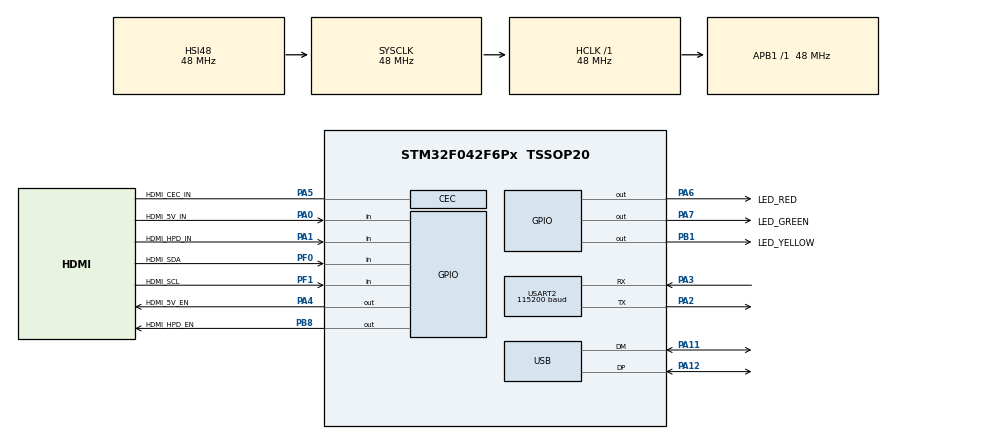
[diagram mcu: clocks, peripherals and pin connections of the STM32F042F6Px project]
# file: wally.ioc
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Mcu.Family=STM32F0
VP_SYS_VS_PINREMAP.Mode=PINREMAP
USB_DEVICE.CLASS_NAME_FS=CDC
NVIC.USB_IRQn=true\:0\:0\:false\:false\:true\:false\:true
USB_DEVICE.VirtualModeFS=Cdc_FS
PA3.GPIO_PuPd=GPIO_PULLUP
PA0.GPIO_Label=HDMI_5V_IN
PA2.GPIO_Speed=GPIO_SPEED_FREQ_LOW
PA11.Mode=Device
PA6.GPIO_Label=LED_RED
PA3.GPIO_Speed=GPIO_SPEED_FREQ_LOW
NVIC.USART2_IRQn=true\:0\:0\:false\:false\:true\:true\:true
USART2.BaudRate=115200
RCC.SYSCLKSource=RCC_SYSCLKSOURCE_HSI48
ProjectManager.StackSize=0x200
PA3.Mode=Asynchronous
PA13.Signal=SYS_SWDIO
PB8.GPIO_Label=HDMI_HPD_EN
PA12.Signal=USB_DP
ProjectManager.TargetToolchain=STM32CubeIDE
PF0-OSC_IN.GPIO_PuPd=GPIO_PULLUP
RCC.HCLKFreq_Value=48000000
VP_USB_DEVICE_VS_USB_DEVICE_CDC_FS.Mode=CDC_FS
PF1-OSC_OUT.GPIO_PuPd=GPIO_PULLUP
PA1.Signal=GPIO_Input
RCC.AHBFreq_Value=48000000
PA5.Signal=CEC
PF0-OSC_IN.GPIO_Label=HDMI_SDA
board=custom
USART2.VirtualMode-Asynchronous=VM_ASYNC
PA14.Mode=Serial_Wire
PB1.GPIO_Label=LED_YELLOW
PF1-OSC_OUT.GPIO_Label=HDMI_SCL
PA1.GPIO_Label=HDMI_HPD_IN
PA13.Mode=Serial_Wire
Mcu.Name=STM32F042F6Px
PA2.Signal=USART2_TX
PA0.Signal=GPIO_Input
PA4.Signal=GPIO_Output
NVIC.CEC_CAN_IRQn=true\:0\:0\:false\:false\:true\:false\:true
RCC.SYSCLKFreq_VALUE=48000000
Mcu.Package=TSSOP20
PA6.Signal=GPIO_Output
PB1.Signal=GPIO_Output
PA7.GPIO_Label=LED_GREEN
PA12.Mode=Device
PA5.GPIO_Label=HDMI_CEC_IN
PA11.Signal=USB_DM
PA14.Signal=SYS_SWCLK
ProjectManager.HeapSize=0x400
RCC.APB1TimFreq_Value=48000000
PB8.Signal=GPIO_Output
PA2.Mode=Asynchronous
PF0-OSC_IN.Signal=GPIO_Input
RCC.APB1Freq_Value=48000000
USB_DEVICE.VirtualMode=Cdc
PA4.GPIO_Label=HDMI_5V_EN
PF1-OSC_OUT.Signal=GPIO_Input
PA3.Signal=USART2_RX
PA5.Mode=CEC_Activate
PA7.Signal=GPIO_Output

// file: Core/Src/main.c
/* USER CODE BEGIN Header */
/**
  ******************************************************************************
  * @file           : main.c
  * @brief          : Main program body
  ******************************************************************************
  * @attention
  *
  * <h2><center>&copy; Copyright (c) 2021 STMicroelectronics.
  * All rights reserved.</center></h2>
  *
  * This software component is licensed by ST under BSD 3-Clause license,
  * the "License"; You may not use this file except in compliance with the
  * License. You may obtain a copy of the License at:
  *                        opensource.org/licenses/BSD-3-Clause
  *
  ******************************************************************************
  */
/* USER CODE END Header */
#include "main.h"

CEC_HandleTypeDef hcec;

UART_HandleTypeDef huart2;

uint8_t cec_receive_buffer[16];

void SystemClock_Config(void);
static void MX_GPIO_Init(void);
static void MX_HDMI_CEC_Init(void);
static void MX_USART2_UART_Init(void);

int main(void)
{

  /* MCU Configuration--------------------------------------------------------*/

  /* Reset of all peripherals, Initializes the Flash interface and the Systick. */
  HAL_Init();

  /* Configure the system clock */
  SystemClock_Config();

  /* Initialize all configured peripherals */
  MX_GPIO_Init();
  MX_HDMI_CEC_Init();
  MX_USART2_UART_Init();
  /* USER CODE BEGIN 2 */
  extern void WallySetup( void );
  WallySetup();
  /* USER CODE END 2 */

  /* Infinite loop */
  while (1)
  {

    /* USER CODE BEGIN 3 */
    extern void WallyLoop( void );
    WallyLoop();
  }
  /* USER CODE END 3 */
}

void SystemClock_Config(void)
{
  RCC_OscInitTypeDef RCC_OscInitStruct = {0};
  RCC_ClkInitTypeDef RCC_ClkInitStruct = {0};
  RCC_PeriphCLKInitTypeDef PeriphClkInit = {0};

  /** Initializes the RCC Oscillators according to the specified parameters
  * in the RCC_OscInitTypeDef structure.
  */
  RCC_OscInitStruct.OscillatorType = RCC_OSCILLATORTYPE_HSI|RCC_OSCILLATORTYPE_HSI48;
  RCC_OscInitStruct.HSIState = RCC_HSI_ON;
  RCC_OscInitStruct.HSI48State = RCC_HSI48_ON;
  RCC_OscInitStruct.HSICalibrationValue = RCC_HSICALIBRATION_DEFAULT;
  RCC_OscInitStruct.PLL.PLLState = RCC_PLL_NONE;
  if (HAL_RCC_OscConfig(&RCC_OscInitStruct) != HAL_OK)
  {
    Error_Handler();
  }
  /** Initializes the CPU, AHB and APB buses clocks
  */
  RCC_ClkInitStruct.ClockType = RCC_CLOCKTYPE_HCLK|RCC_CLOCKTYPE_SYSCLK
                              |RCC_CLOCKTYPE_PCLK1;
  RCC_ClkInitStruct.SYSCLKSource = RCC_SYSCLKSOURCE_HSI48;
  RCC_ClkInitStruct.AHBCLKDivider = RCC_SYSCLK_DIV1;
  RCC_ClkInitStruct.APB1CLKDivider = RCC_HCLK_DIV1;

  if (HAL_RCC_ClockConfig(&RCC_ClkInitStruct, FLASH_LATENCY_1) != HAL_OK)
  {
    Error_Handler();
  }
  PeriphClkInit.PeriphClockSelection = RCC_PERIPHCLK_CEC;
  PeriphClkInit.CecClockSelection = RCC_CECCLKSOURCE_HSI;
  if (HAL_RCCEx_PeriphCLKConfig(&PeriphClkInit) != HAL_OK)
  {
    Error_Handler();
  }
}

static void MX_HDMI_CEC_Init(void)
{

  hcec.Instance = CEC;
  hcec.Init.SignalFreeTime = CEC_DEFAULT_SFT;
  hcec.Init.Tolerance = CEC_STANDARD_TOLERANCE;
  hcec.Init.BRERxStop = CEC_RX_STOP_ON_BRE;
  hcec.Init.BREErrorBitGen = CEC_BRE_ERRORBIT_NO_GENERATION;
  hcec.Init.LBPEErrorBitGen = CEC_LBPE_ERRORBIT_NO_GENERATION;
  hcec.Init.BroadcastMsgNoErrorBitGen = CEC_BROADCASTERROR_ERRORBIT_GENERATION;
  hcec.Init.SignalFreeTimeOption = CEC_SFT_START_ON_TXSOM;
  hcec.Init.ListenMode = CEC_FULL_LISTENING_MODE;
  hcec.Init.OwnAddress = CEC_OWN_ADDRESS_NONE;
  hcec.Init.RxBuffer = cec_receive_buffer;
  if (HAL_CEC_Init(&hcec) != HAL_OK)
  {
    Error_Handler();
  }

}

static void MX_USART2_UART_Init(void)
{

  huart2.Instance = USART2;
  huart2.Init.BaudRate = 115200;
  huart2.Init.WordLength = UART_WORDLENGTH_8B;
  huart2.Init.StopBits = UART_STOPBITS_1;
  huart2.Init.Parity = UART_PARITY_NONE;
  huart2.Init.Mode = UART_MODE_TX_RX;
  huart2.Init.HwFlowCtl = UART_HWCONTROL_NONE;
  huart2.Init.OverSampling = UART_OVERSAMPLING_16;
  huart2.Init.OneBitSampling = UART_ONE_BIT_SAMPLE_DISABLE;
  huart2.AdvancedInit.AdvFeatureInit = UART_ADVFEATURE_NO_INIT;
  if (HAL_UART_Init(&huart2) != HAL_OK)
  {
    Error_Handler();
  }

}

static void MX_GPIO_Init(void)
{
  GPIO_InitTypeDef GPIO_InitStruct = {0};

  /* GPIO Ports Clock Enable */
  __HAL_RCC_GPIOB_CLK_ENABLE();
  __HAL_RCC_GPIOF_CLK_ENABLE();
  __HAL_RCC_GPIOA_CLK_ENABLE();

  /*Configure GPIO pin Output Level */
  HAL_GPIO_WritePin(GPIOB, HDMI_HPD_EN_Pin|LED_YELLOW_Pin, GPIO_PIN_RESET);

  /*Configure GPIO pin Output Level */
  HAL_GPIO_WritePin(GPIOA, HDMI_5V_EN_Pin|LED_RED_Pin|LED_GREEN_Pin, GPIO_PIN_RESET);

  /*Configure GPIO pins : HDMI_HPD_EN_Pin LED_YELLOW_Pin */
  GPIO_InitStruct.Pin = HDMI_HPD_EN_Pin|LED_YELLOW_Pin;
  GPIO_InitStruct.Mode = GPIO_MODE_OUTPUT_PP;
  GPIO_InitStruct.Pull = GPIO_NOPULL;
  GPIO_InitStruct.Speed = GPIO_SPEED_FREQ_LOW;
  HAL_GPIO_Init(GPIOB, &GPIO_InitStruct);

  /*Configure GPIO pins : HDMI_SDA_Pin HDMI_SCL_Pin */
  GPIO_InitStruct.Pin = HDMI_SDA_Pin|HDMI_SCL_Pin;
  GPIO_InitStruct.Mode = GPIO_MODE_INPUT;
  GPIO_InitStruct.Pull = GPIO_PULLUP;
  HAL_GPIO_Init(GPIOF, &GPIO_InitStruct);

  /*Configure GPIO pins : HDMI_5V_IN_Pin HDMI_HPD_IN_Pin */
  GPIO_InitStruct.Pin = HDMI_5V_IN_Pin|HDMI_HPD_IN_Pin;
  GPIO_InitStruct.Mode = GPIO_MODE_INPUT;
  GPIO_InitStruct.Pull = GPIO_NOPULL;
  HAL_GPIO_Init(GPIOA, &GPIO_InitStruct);

  /*Configure GPIO pins : HDMI_5V_EN_Pin LED_RED_Pin LED_GREEN_Pin */
  GPIO_InitStruct.Pin = HDMI_5V_EN_Pin|LED_RED_Pin|LED_GREEN_Pin;
  GPIO_InitStruct.Mode = GPIO_MODE_OUTPUT_PP;
  GPIO_InitStruct.Pull = GPIO_NOPULL;
  GPIO_InitStruct.Speed = GPIO_SPEED_FREQ_LOW;
  HAL_GPIO_Init(GPIOA, &GPIO_InitStruct);

}

void Error_Handler(void)
{
  __disable_irq();
  while (1)
  {
  }
}

/************************ (C) COPYRIGHT STMicroelectronics *****END OF FILE****/
